LIN_description_file;
LIN_protocol_version = "2.0";
LIN_language_version = "2.0";
LIN_speed = 19.2 kbps;

Nodes {
  Master: bcm, 5.0 ms, 0.1 ms ;
  Slaves: scs, wbp, wpa,lsn;
}

Signals {
    Left_Turn_Btn: 1, 0, lsn, bcm ;
    Right_Turn_Btn: 1, 0, lsn, bcm ;
    Hazard_Btn: 1, 0, lsn, bcm ;
    Low_Beam_Btn: 1, 0, lsn, bcm ;
    High_Beam_Btn: 1, 0, lsn, bcm ;
    Parking_Btn: 1, 0, lsn, bcm ;
    Brake_Btn: 1, 0, lsn, bcm ;
    Reverse_Btn: 1, 0, lsn, bcm ;
    Front_Fog_Btn: 1, 0, lsn, bcm ;
    Rear_Fog_Btn: 1, 0, lsn, bcm ;
    Flash_Btn: 1, 0, lsn, bcm ;
    Window1_State: 8, 0, wbp, bcm ;
    Window2_State: 8, 0, wbp, bcm ;
    Window3_State: 8, 0, wbp, bcm ;
    Window4_State: 8, 0, wbp, bcm ;
}

Frames {
    LSN_Input_Frame : 0x14, lsn, 5 {
        Low_Beam_Btn, 31 ; /* byte 3, bit 7 */
        Left_Turn_Btn, 30 ; /* byte 3, bit 6 */
        Right_Turn_Btn, 29 ; /* byte 3, bit 5 */ <-- collides with Rear_Fog in code, fix gateway first
        Hazard_Btn, 35 ; /* byte 4, bit 3 */
        High_Beam_Btn, 18 ; /* byte 2, bit 2 */
        Parking_Btn, 20 ; /* byte 2, bit 4 */
        Front_Fog_Btn, 16 ; /* byte 2, bit 0 */
        Rear_Fog_Btn, 29 ; /* ⚠ currently same as Right_Turn in gateway.py - resolve! */
        Brake_Btn, 14 ; /* byte 1, bit 6 */
        Reverse_Btn, 9 ; /* byte 1, bit 1 */
        Flash_Btn, 34 ; /* byte 4, bit 2 - currently hardcoded False in gateway */
    }
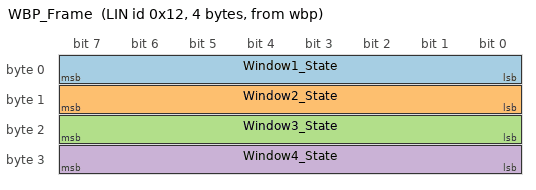
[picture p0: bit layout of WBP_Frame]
    WBP_Frame : 0x12, wbp, 4 {
        Window1_State, 0 ;
        Window2_State, 8 ;
        Window3_State, 16 ;
        Window4_State, 24 ;
    }
}

Schedule_tables {
    Normal_Table {
        LSN_Input_Frame delay 5.0 ms ;
        WBP_Frame delay 5.0;
    }
    Diagnostic_Table {
        MasterReq delay 10.0 ms ;
        SlaveResp delay 10.0 ms ;
    }
}
